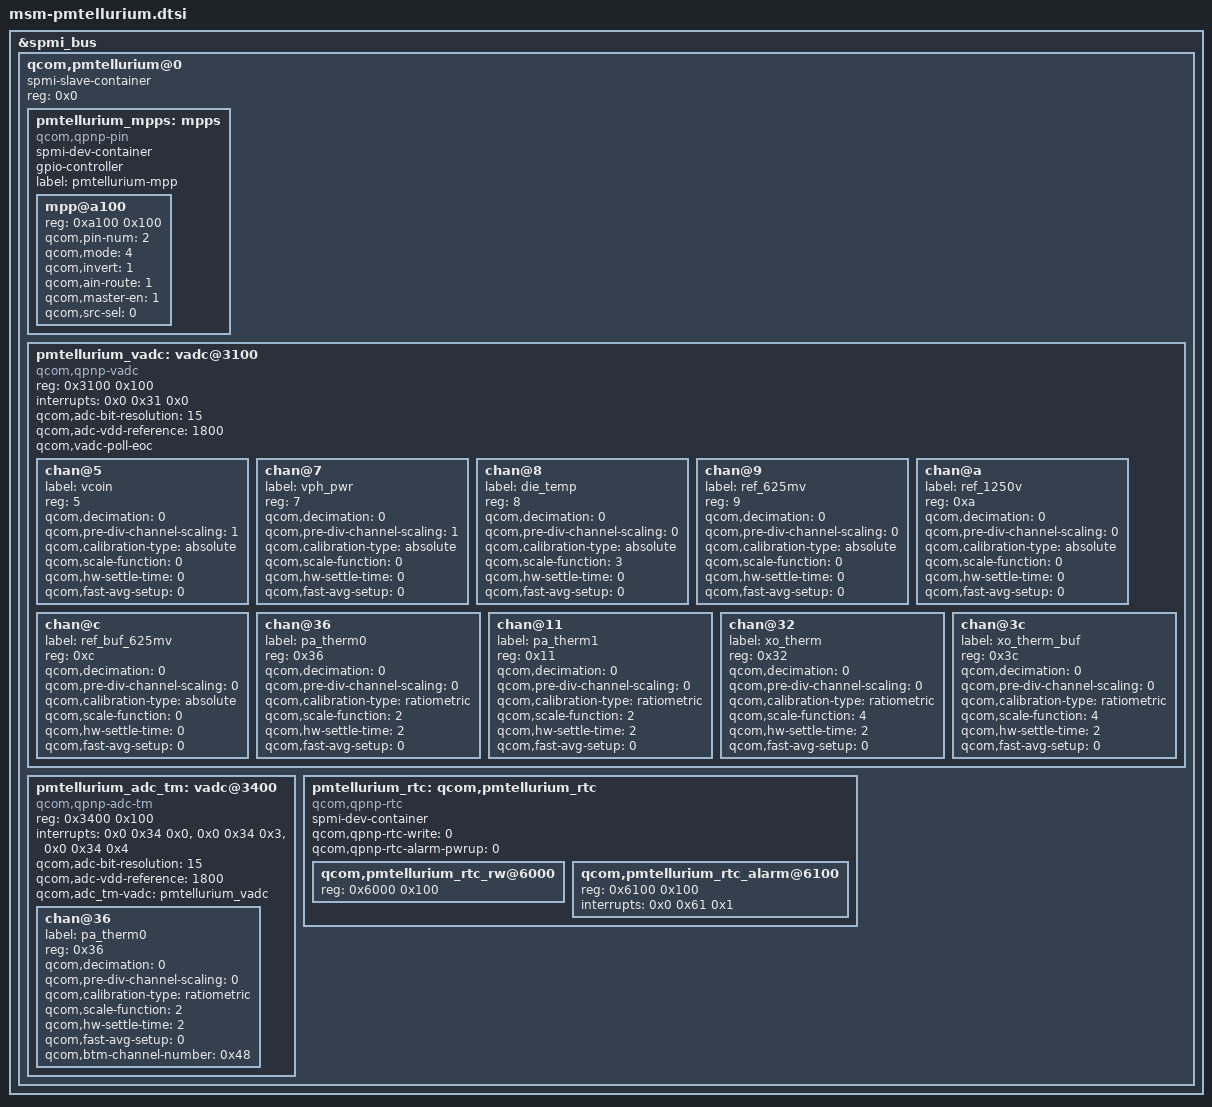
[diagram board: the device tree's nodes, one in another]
/* Copyright (c) 2015, The Linux Foundation. All rights reserved.
 *
 * This program is free software; you can redistribute it and/or modify
 * it under the terms of the GNU General Public License version 2 and
 * only version 2 as published by the Free Software Foundation.
 *
 * This program is distributed in the hope that it will be useful,
 * but WITHOUT ANY WARRANTY; without even the implied warranty of
 * MERCHANTABILITY or FITNESS FOR A PARTICULAR PURPOSE.  See the
 * GNU General Public License for more details.
 */

&spmi_bus {

	qcom,pmtellurium@0 {
		spmi-slave-container;
		reg = <0x0>;
		#address-cells = <1>;
		#size-cells = <1>;

		pmtellurium_mpps: mpps {
			compatible = "qcom,qpnp-pin";
			spmi-dev-container;
			gpio-controller;
			#gpio-cells = <2>;
			#address-cells = <1>;
			#size-cells = <1>;
			label = "pmtellurium-mpp";

			mpp@a100 {
				/* MPP2 - PA_THERM config */
				reg = <0xa100 0x100>;
				qcom,pin-num = <2>;
				qcom,mode = <4>; /* AIN input */
				qcom,invert = <1>; /* Enable MPP */
				qcom,ain-route = <1>; /* AMUX 6 */
				qcom,master-en = <1>;
				qcom,src-sel = <0>; /* Function constant */
			};
		};

		pmtellurium_vadc: vadc@3100 {
			compatible = "qcom,qpnp-vadc";
			reg = <0x3100 0x100>;
			#address-cells = <1>;
			#size-cells = <0>;
			interrupts = <0x0 0x31 0x0>;
			interrupt-names = "eoc-int-en-set";
			qcom,adc-bit-resolution = <15>;
			qcom,adc-vdd-reference = <1800>;
			qcom,vadc-poll-eoc;

			chan@5 {
				label = "vcoin";
				reg = <5>;
				qcom,decimation = <0>;
				qcom,pre-div-channel-scaling = <1>;
				qcom,calibration-type = "absolute";
				qcom,scale-function = <0>;
				qcom,hw-settle-time = <0>;
				qcom,fast-avg-setup = <0>;
			};

			chan@7 {
				label = "vph_pwr";
				reg = <7>;
				qcom,decimation = <0>;
				qcom,pre-div-channel-scaling = <1>;
				qcom,calibration-type = "absolute";
				qcom,scale-function = <0>;
				qcom,hw-settle-time = <0>;
				qcom,fast-avg-setup = <0>;
			};

			chan@8 {
				label = "die_temp";
				reg = <8>;
				qcom,decimation = <0>;
				qcom,pre-div-channel-scaling = <0>;
				qcom,calibration-type = "absolute";
				qcom,scale-function = <3>;
				qcom,hw-settle-time = <0>;
				qcom,fast-avg-setup = <0>;
			};

			chan@9 {
				label = "ref_625mv";
				reg = <9>;
				qcom,decimation = <0>;
				qcom,pre-div-channel-scaling = <0>;
				qcom,calibration-type = "absolute";
				qcom,scale-function = <0>;
				qcom,hw-settle-time = <0>;
				qcom,fast-avg-setup = <0>;
			};

			chan@a {
				label = "ref_1250v";
				reg = <0xa>;
				qcom,decimation = <0>;
				qcom,pre-div-channel-scaling = <0>;
				qcom,calibration-type = "absolute";
				qcom,scale-function = <0>;
				qcom,hw-settle-time = <0>;
				qcom,fast-avg-setup = <0>;
			};

			chan@c {
				label = "ref_buf_625mv";
				reg = <0xc>;
				qcom,decimation = <0>;
				qcom,pre-div-channel-scaling = <0>;
				qcom,calibration-type = "absolute";
				qcom,scale-function = <0>;
				qcom,hw-settle-time = <0>;
				qcom,fast-avg-setup = <0>;
			};

			chan@36 {
				label = "pa_therm0";
				reg = <0x36>;
				qcom,decimation = <0>;
				qcom,pre-div-channel-scaling = <0>;
				qcom,calibration-type = "ratiometric";
				qcom,scale-function = <2>;
				qcom,hw-settle-time = <2>;
				qcom,fast-avg-setup = <0>;
			};

			chan@11 {
				label = "pa_therm1";
				reg = <0x11>;
				qcom,decimation = <0>;
				qcom,pre-div-channel-scaling = <0>;
				qcom,calibration-type = "ratiometric";
				qcom,scale-function = <2>;
				qcom,hw-settle-time = <2>;
				qcom,fast-avg-setup = <0>;
			};

			chan@32 {
				label = "xo_therm";
				reg = <0x32>;
				qcom,decimation = <0>;
				qcom,pre-div-channel-scaling = <0>;
				qcom,calibration-type = "ratiometric";
				qcom,scale-function = <4>;
				qcom,hw-settle-time = <2>;
				qcom,fast-avg-setup = <0>;
			};

			chan@3c {
				label = "xo_therm_buf";
				reg = <0x3c>;
				qcom,decimation = <0>;
				qcom,pre-div-channel-scaling = <0>;
				qcom,calibration-type = "ratiometric";
				qcom,scale-function = <4>;
				qcom,hw-settle-time = <2>;
				qcom,fast-avg-setup = <0>;
			};
		};

		pmtellurium_adc_tm: vadc@3400 {
			compatible = "qcom,qpnp-adc-tm";
			reg = <0x3400 0x100>;
			#address-cells = <1>;
			#size-cells = <0>;
			interrupts =	<0x0 0x34 0x0>,
					<0x0 0x34 0x3>,
					<0x0 0x34 0x4>;
			interrupt-names =	"eoc-int-en-set",
						"high-thr-en-set",
						"low-thr-en-set";
			qcom,adc-bit-resolution = <15>;
			qcom,adc-vdd-reference = <1800>;
			qcom,adc_tm-vadc = <&pmtellurium_vadc>;

			chan@36 {
				label = "pa_therm0";
				reg = <0x36>;
				qcom,decimation = <0>;
				qcom,pre-div-channel-scaling = <0>;
				qcom,calibration-type = "ratiometric";
				qcom,scale-function = <2>;
				qcom,hw-settle-time = <2>;
				qcom,fast-avg-setup = <0>;
				qcom,btm-channel-number = <0x48>;
			};
		};

		pmtellurium_rtc: qcom,pmtellurium_rtc {
			spmi-dev-container;
			compatible = "qcom,qpnp-rtc";
			#address-cells = <1>;
			#size-cells = <1>;
			qcom,qpnp-rtc-write = <0>;
			qcom,qpnp-rtc-alarm-pwrup = <0>;

			qcom,pmtellurium_rtc_rw@6000 {
				reg = <0x6000 0x100>;
			};

			qcom,pmtellurium_rtc_alarm@6100 {
				reg = <0x6100 0x100>;
				interrupts = <0x0 0x61 0x1>;
			};
		};
	};
};
